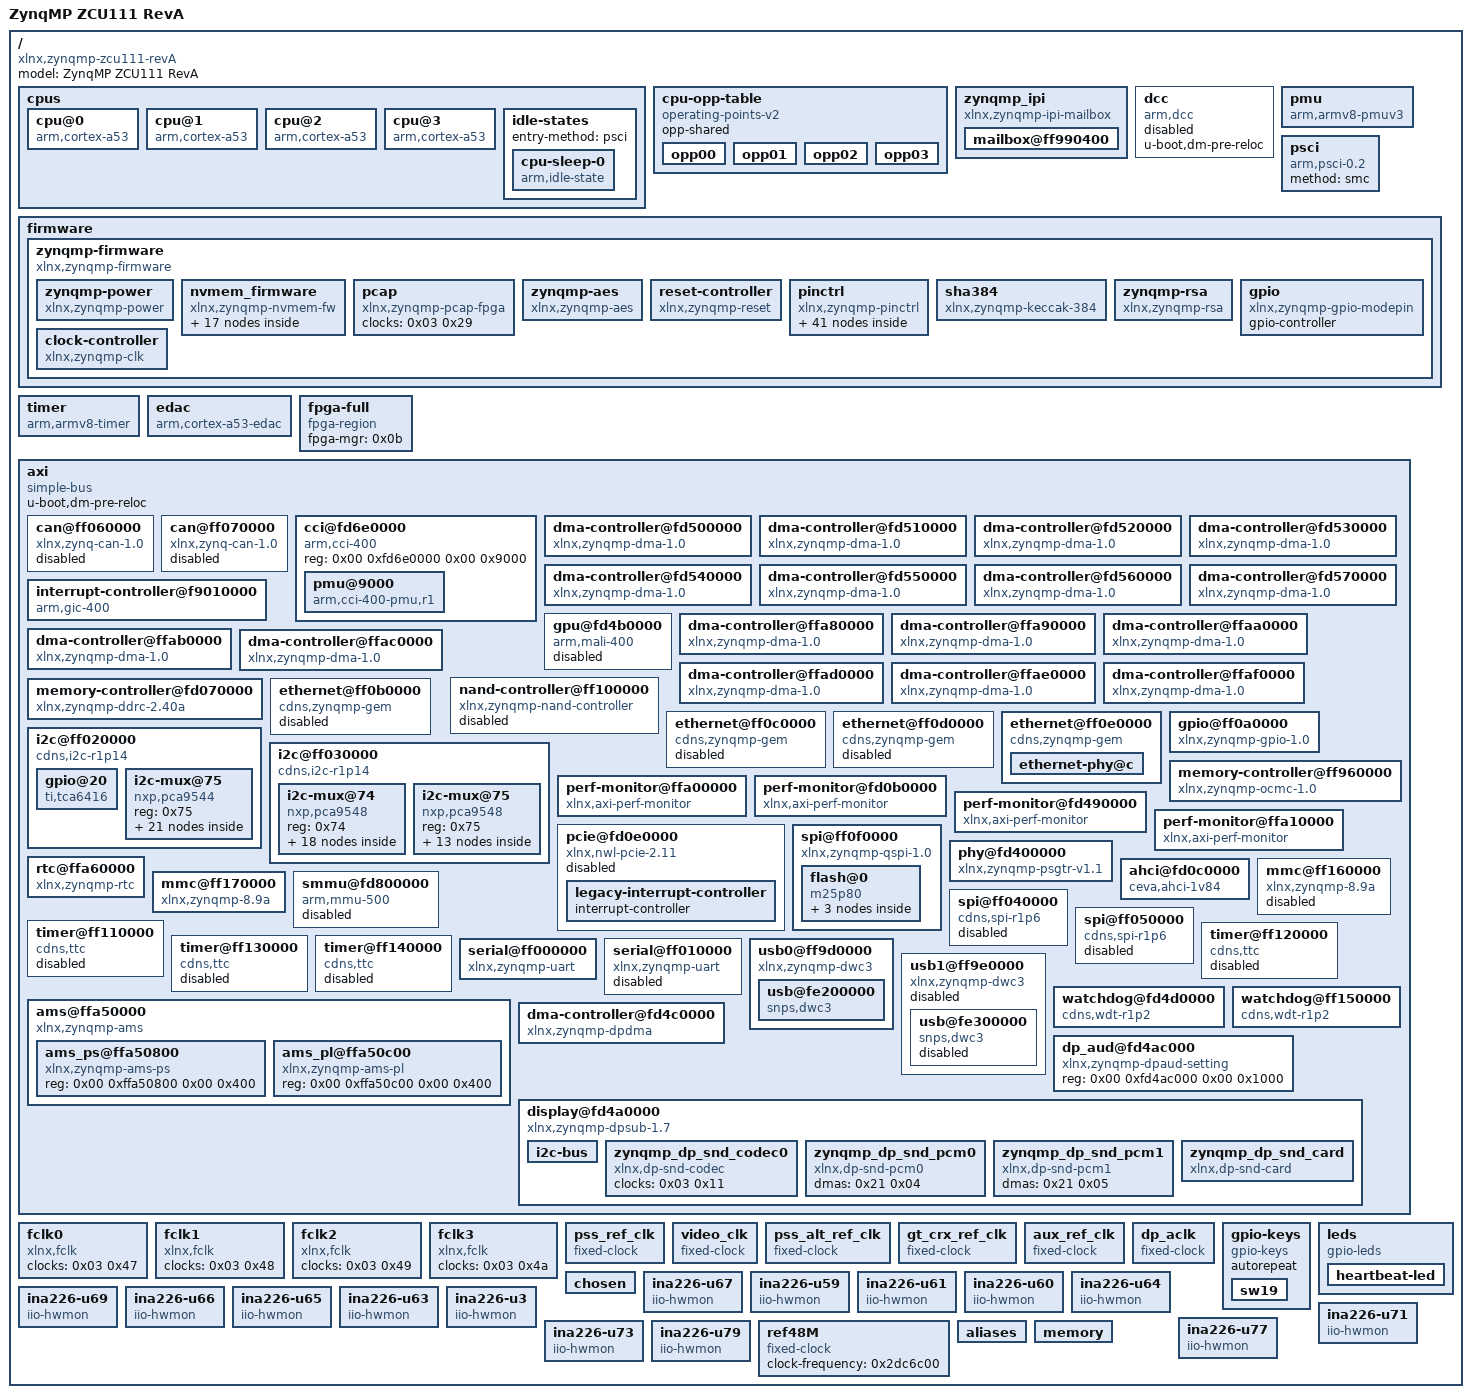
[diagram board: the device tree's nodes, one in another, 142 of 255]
/dts-v1/;

/ {
	compatible = "xlnx,zynqmp-zcu111-revA\0xlnx,zynqmp-zcu111\0xlnx,zynqmp";
	#address-cells = <0x02>;
	#size-cells = <0x02>;
	model = "ZynqMP ZCU111 RevA";

	cpus {
		#address-cells = <0x01>;
		#size-cells = <0x00>;

		cpu@0 {
			compatible = "arm,cortex-a53";
			device_type = "cpu";
			enable-method = "psci";
			operating-points-v2 = <0x01>;
			reg = <0x00>;
			cpu-idle-states = <0x02>;
			clocks = <0x03 0x0a>;
			phandle = <0x34>;
		};

		cpu@1 {
			compatible = "arm,cortex-a53";
			device_type = "cpu";
			enable-method = "psci";
			reg = <0x01>;
			operating-points-v2 = <0x01>;
			cpu-idle-states = <0x02>;
			phandle = <0x35>;
		};

		cpu@2 {
			compatible = "arm,cortex-a53";
			device_type = "cpu";
			enable-method = "psci";
			reg = <0x02>;
			operating-points-v2 = <0x01>;
			cpu-idle-states = <0x02>;
			phandle = <0x36>;
		};

		cpu@3 {
			compatible = "arm,cortex-a53";
			device_type = "cpu";
			enable-method = "psci";
			reg = <0x03>;
			operating-points-v2 = <0x01>;
			cpu-idle-states = <0x02>;
			phandle = <0x37>;
		};

		idle-states {
			entry-method = "psci";

			cpu-sleep-0 {
				compatible = "arm,idle-state";
				arm,psci-suspend-param = <0x40000000>;
				local-timer-stop;
				entry-latency-us = <0x12c>;
				exit-latency-us = <0x258>;
				min-residency-us = <0x2710>;
				phandle = <0x02>;
			};
		};
	};

	cpu-opp-table {
		compatible = "operating-points-v2";
		opp-shared;
		phandle = <0x01>;

		opp00 {
			opp-hz = <0x00 0x47868bf4>;
			opp-microvolt = <0xf4240>;
			clock-latency-ns = <0x7a120>;
		};

		opp01 {
			opp-hz = <0x00 0x23c345fa>;
			opp-microvolt = <0xf4240>;
			clock-latency-ns = <0x7a120>;
		};

		opp02 {
			opp-hz = <0x00 0x17d783fc>;
			opp-microvolt = <0xf4240>;
			clock-latency-ns = <0x7a120>;
		};

		opp03 {
			opp-hz = <0x00 0x11e1a2fd>;
			opp-microvolt = <0xf4240>;
			clock-latency-ns = <0x7a120>;
		};
	};

	zynqmp_ipi {
		u-boot,dm-pre-reloc;
		compatible = "xlnx,zynqmp-ipi-mailbox";
		interrupt-parent = <0x04>;
		interrupts = <0x00 0x23 0x04>;
		xlnx,ipi-id = <0x00>;
		#address-cells = <0x02>;
		#size-cells = <0x02>;
		ranges;
		phandle = <0x38>;

		mailbox@ff990400 {
			u-boot,dm-pre-reloc;
			reg = <0x00 0xff9905c0 0x00 0x20 0x00 0xff9905e0 0x00 0x20 0x00 0xff990e80 0x00 0x20 0x00 0xff990ea0 0x00 0x20>;
			reg-names = "local_request_region\0local_response_region\0remote_request_region\0remote_response_region";
			#mbox-cells = <0x01>;
			xlnx,ipi-id = <0x04>;
			phandle = <0x05>;
		};
	};

	dcc {
		compatible = "arm,dcc";
		status = "disabled";
		u-boot,dm-pre-reloc;
		phandle = <0x39>;
	};

	pmu {
		compatible = "arm,armv8-pmuv3";
		interrupt-parent = <0x04>;
		interrupts = <0x00 0x8f 0x04 0x00 0x90 0x04 0x00 0x91 0x04 0x00 0x92 0x04>;
	};

	psci {
		compatible = "arm,psci-0.2";
		method = "smc";
	};

	firmware {

		zynqmp-firmware {
			compatible = "xlnx,zynqmp-firmware";
			u-boot,dm-pre-reloc;
			method = "smc";
			#power-domain-cells = <0x01>;
			phandle = <0x0c>;

			zynqmp-power {
				u-boot,dm-pre-reloc;
				compatible = "xlnx,zynqmp-power";
				interrupt-parent = <0x04>;
				interrupts = <0x00 0x23 0x04>;
				mboxes = <0x05 0x00 0x05 0x01>;
				mbox-names = "tx\0rx";
				phandle = <0x3a>;
			};

			nvmem_firmware {
				compatible = "xlnx,zynqmp-nvmem-fw";
				#address-cells = <0x01>;
				#size-cells = <0x01>;

				soc_revision@0 {
					reg = <0x00 0x04>;
					phandle = <0x3b>;
				};

				efuse_dna@c {
					reg = <0x0c 0x0c>;
					phandle = <0x3c>;
				};

				efuse_usr0@20 {
					reg = <0x20 0x04>;
					phandle = <0x3d>;
				};

				efuse_usr1@24 {
					reg = <0x24 0x04>;
					phandle = <0x3e>;
				};

				efuse_usr2@28 {
					reg = <0x28 0x04>;
					phandle = <0x3f>;
				};

				efuse_usr3@2c {
					reg = <0x2c 0x04>;
					phandle = <0x40>;
				};

				efuse_usr4@30 {
					reg = <0x30 0x04>;
					phandle = <0x41>;
				};

				efuse_usr5@34 {
					reg = <0x34 0x04>;
					phandle = <0x42>;
				};

				efuse_usr6@38 {
					reg = <0x38 0x04>;
					phandle = <0x43>;
				};

				efuse_usr7@3c {
					reg = <0x3c 0x04>;
					phandle = <0x44>;
				};

				efuse_miscusr@40 {
					reg = <0x40 0x04>;
					phandle = <0x45>;
				};

				efuse_chash@50 {
					reg = <0x50 0x04>;
					phandle = <0x46>;
				};

				efuse_pufmisc@54 {
					reg = <0x54 0x04>;
					phandle = <0x47>;
				};

				efuse_sec@58 {
					reg = <0x58 0x04>;
					phandle = <0x48>;
				};

				efuse_spkid@5c {
					reg = <0x5c 0x04>;
					phandle = <0x49>;
				};

				efuse_ppk0hash@a0 {
					reg = <0xa0 0x30>;
					phandle = <0x4a>;
				};

				efuse_ppk1hash@d0 {
					reg = <0xd0 0x30>;
					phandle = <0x4b>;
				};
			};

			pcap {
				compatible = "xlnx,zynqmp-pcap-fpga";
				clock-names = "ref_clk";
				clocks = <0x03 0x29>;
				phandle = <0x0b>;
			};

			zynqmp-aes {
				compatible = "xlnx,zynqmp-aes";
				phandle = <0x4c>;
			};

			reset-controller {
				compatible = "xlnx,zynqmp-reset";
				#reset-cells = <0x01>;
				phandle = <0x0e>;
			};

			pinctrl {
				compatible = "xlnx,zynqmp-pinctrl";
				status = "okay";
				phandle = <0x4d>;

				i2c0-default {
					phandle = <0x12>;

					mux {
						groups = "i2c0_3_grp";
						function = "i2c0";
					};

					conf {
						groups = "i2c0_3_grp";
						bias-pull-up;
						slew-rate = <0x01>;
						power-source = <0x01>;
					};
				};

				i2c0-gpio {
					phandle = <0x13>;

					mux {
						groups = "gpio0_14_grp\0gpio0_15_grp";
						function = "gpio0";
					};

					conf {
						groups = "gpio0_14_grp\0gpio0_15_grp";
						slew-rate = <0x01>;
						power-source = <0x01>;
					};
				};

				i2c1-default {
					phandle = <0x15>;

					mux {
						groups = "i2c1_4_grp";
						function = "i2c1";
					};

					conf {
						groups = "i2c1_4_grp";
						bias-pull-up;
						slew-rate = <0x01>;
						power-source = <0x01>;
					};
				};

				i2c1-gpio {
					phandle = <0x16>;

					mux {
						groups = "gpio0_16_grp\0gpio0_17_grp";
						function = "gpio0";
					};

					conf {
						groups = "gpio0_16_grp\0gpio0_17_grp";
						slew-rate = <0x01>;
						power-source = <0x01>;
					};
				};

				uart0-default {
					phandle = <0x1d>;

					mux {
						groups = "uart0_4_grp";
						function = "uart0";
					};

					conf {
						groups = "uart0_4_grp";
						slew-rate = <0x01>;
						power-source = <0x01>;
					};

					conf-rx {
						pins = "MIO18";
						bias-high-impedance;
					};

					conf-tx {
						pins = "MIO19";
						bias-disable;
					};
				};

				usb0-default {
					phandle = <0x1f>;

					mux {
						groups = "usb0_0_grp";
						function = "usb0";
					};

					conf {
						groups = "usb0_0_grp";
						slew-rate = <0x01>;
						power-source = <0x01>;
					};

					conf-rx {
						pins = "MIO52\0MIO53\0MIO55";
						bias-high-impedance;
					};

					conf-tx {
						pins = "MIO54\0MIO56\0MIO57\0MIO58\0MIO59\0MIO60\0MIO61\0MIO62\0MIO63";
						bias-disable;
					};
				};

				gem3-default {
					phandle = <0x10>;

					mux {
						function = "ethernet3";
						groups = "ethernet3_0_grp";
					};

					conf {
						groups = "ethernet3_0_grp";
						slew-rate = <0x01>;
						power-source = <0x01>;
					};

					conf-rx {
						pins = "MIO70\0MIO71\0MIO72\0MIO73\0MIO74\0MIO75";
						bias-high-impedance;
						low-power-disable;
					};

					conf-tx {
						pins = "MIO64\0MIO65\0MIO66\0MIO67\0MIO68\0MIO69";
						bias-disable;
						low-power-enable;
					};

					mux-mdio {
						function = "mdio3";
						groups = "mdio3_0_grp";
					};

					conf-mdio {
						groups = "mdio3_0_grp";
						slew-rate = <0x01>;
						power-source = <0x01>;
						bias-disable;
					};
				};

				sdhci1-default {
					phandle = <0x1c>;

					mux {
						groups = "sdio1_0_grp";
						function = "sdio1";
					};

					conf {
						groups = "sdio1_0_grp";
						slew-rate = <0x01>;
						power-source = <0x01>;
						bias-disable;
					};

					mux-cd {
						groups = "sdio1_cd_0_grp";
						function = "sdio1_cd";
					};

					conf-cd {
						groups = "sdio1_cd_0_grp";
						bias-high-impedance;
						bias-pull-up;
						slew-rate = <0x01>;
						power-source = <0x01>;
					};
				};

				gpio-default {
					phandle = <0x11>;

					mux {
						function = "gpio0";
						groups = "gpio0_22_grp\0gpio0_23_grp";
					};

					conf {
						groups = "gpio0_22_grp\0gpio0_23_grp";
						slew-rate = <0x01>;
						power-source = <0x01>;
					};

					mux-msp {
						function = "gpio0";
						groups = "gpio0_13_grp\0gpio0_38_grp";
					};

					conf-msp {
						groups = "gpio0_13_grp\0gpio0_38_grp";
						slew-rate = <0x01>;
						power-source = <0x01>;
					};

					conf-pull-up {
						pins = "MIO22";
						bias-pull-up;
					};

					conf-pull-none {
						pins = "MIO13\0MIO23\0MIO38";
						bias-disable;
					};
				};
			};

			sha384 {
				compatible = "xlnx,zynqmp-keccak-384";
				phandle = <0x4e>;
			};

			zynqmp-rsa {
				compatible = "xlnx,zynqmp-rsa";
				phandle = <0x4f>;
			};

			gpio {
				compatible = "xlnx,zynqmp-gpio-modepin";
				gpio-controller;
				#gpio-cells = <0x02>;
				phandle = <0x1e>;
			};

			clock-controller {
				u-boot,dm-pre-reloc;
				#clock-cells = <0x01>;
				compatible = "xlnx,zynqmp-clk";
				clocks = <0x06 0x07 0x08 0x09 0x0a>;
				clock-names = "pss_ref_clk\0video_clk\0pss_alt_ref_clk\0aux_ref_clk\0gt_crx_ref_clk";
				phandle = <0x03>;
			};
		};
	};

	timer {
		compatible = "arm,armv8-timer";
		interrupt-parent = <0x04>;
		interrupts = <0x01 0x0d 0xf08 0x01 0x0e 0xf08 0x01 0x0b 0xf08 0x01 0x0a 0xf08>;
	};

	edac {
		compatible = "arm,cortex-a53-edac";
	};

	fpga-full {
		compatible = "fpga-region";
		fpga-mgr = <0x0b>;
		#address-cells = <0x02>;
		#size-cells = <0x02>;
		ranges;
		phandle = <0x50>;
	};

	axi {
		compatible = "simple-bus";
		u-boot,dm-pre-reloc;
		#address-cells = <0x02>;
		#size-cells = <0x02>;
		ranges;
		phandle = <0x51>;

		can@ff060000 {
			compatible = "xlnx,zynq-can-1.0";
			status = "disabled";
			clock-names = "can_clk\0pclk";
			reg = <0x00 0xff060000 0x00 0x1000>;
			interrupts = <0x00 0x17 0x04>;
			interrupt-parent = <0x04>;
			tx-fifo-depth = <0x40>;
			rx-fifo-depth = <0x40>;
			power-domains = <0x0c 0x2f>;
			clocks = <0x03 0x3f 0x03 0x1f>;
			phandle = <0x52>;
		};

		can@ff070000 {
			compatible = "xlnx,zynq-can-1.0";
			status = "disabled";
			clock-names = "can_clk\0pclk";
			reg = <0x00 0xff070000 0x00 0x1000>;
			interrupts = <0x00 0x18 0x04>;
			interrupt-parent = <0x04>;
			tx-fifo-depth = <0x40>;
			rx-fifo-depth = <0x40>;
			power-domains = <0x0c 0x30>;
			clocks = <0x03 0x40 0x03 0x1f>;
			phandle = <0x53>;
		};

		cci@fd6e0000 {
			compatible = "arm,cci-400";
			status = "okay";
			reg = <0x00 0xfd6e0000 0x00 0x9000>;
			ranges = <0x00 0x00 0xfd6e0000 0x10000>;
			#address-cells = <0x01>;
			#size-cells = <0x01>;
			phandle = <0x54>;

			pmu@9000 {
				compatible = "arm,cci-400-pmu,r1";
				reg = <0x9000 0x5000>;
				interrupt-parent = <0x04>;
				interrupts = <0x00 0x7b 0x04 0x00 0x7b 0x04 0x00 0x7b 0x04 0x00 0x7b 0x04 0x00 0x7b 0x04>;
			};
		};

		dma-controller@fd500000 {
			status = "okay";
			compatible = "xlnx,zynqmp-dma-1.0";
			reg = <0x00 0xfd500000 0x00 0x1000>;
			interrupt-parent = <0x04>;
			interrupts = <0x00 0x7c 0x04>;
			clock-names = "clk_main\0clk_apb";
			xlnx,bus-width = <0x80>;
			#stream-id-cells = <0x01>;
			iommus = <0x0d 0x14e8>;
			power-domains = <0x0c 0x2a>;
			#dma-cells = <0x01>;
			clocks = <0x03 0x13 0x03 0x1f>;
			phandle = <0x55>;
		};

		dma-controller@fd510000 {
			status = "okay";
			compatible = "xlnx,zynqmp-dma-1.0";
			reg = <0x00 0xfd510000 0x00 0x1000>;
			interrupt-parent = <0x04>;
			interrupts = <0x00 0x7d 0x04>;
			clock-names = "clk_main\0clk_apb";
			xlnx,bus-width = <0x80>;
			#stream-id-cells = <0x01>;
			iommus = <0x0d 0x14e9>;
			power-domains = <0x0c 0x2a>;
			#dma-cells = <0x01>;
			clocks = <0x03 0x13 0x03 0x1f>;
			phandle = <0x56>;
		};

		dma-controller@fd520000 {
			status = "okay";
			compatible = "xlnx,zynqmp-dma-1.0";
			reg = <0x00 0xfd520000 0x00 0x1000>;
			interrupt-parent = <0x04>;
			interrupts = <0x00 0x7e 0x04>;
			clock-names = "clk_main\0clk_apb";
			xlnx,bus-width = <0x80>;
			#stream-id-cells = <0x01>;
			iommus = <0x0d 0x14ea>;
			power-domains = <0x0c 0x2a>;
			#dma-cells = <0x01>;
			clocks = <0x03 0x13 0x03 0x1f>;
			phandle = <0x57>;
		};

		dma-controller@fd530000 {
			status = "okay";
			compatible = "xlnx,zynqmp-dma-1.0";
			reg = <0x00 0xfd530000 0x00 0x1000>;
			interrupt-parent = <0x04>;
			interrupts = <0x00 0x7f 0x04>;
			clock-names = "clk_main\0clk_apb";
			xlnx,bus-width = <0x80>;
			#stream-id-cells = <0x01>;
			iommus = <0x0d 0x14eb>;
			power-domains = <0x0c 0x2a>;
			#dma-cells = <0x01>;
			clocks = <0x03 0x13 0x03 0x1f>;
			phandle = <0x58>;
		};

		dma-controller@fd540000 {
			status = "okay";
			compatible = "xlnx,zynqmp-dma-1.0";
			reg = <0x00 0xfd540000 0x00 0x1000>;
			interrupt-parent = <0x04>;
			interrupts = <0x00 0x80 0x04>;
			clock-names = "clk_main\0clk_apb";
			xlnx,bus-width = <0x80>;
			#stream-id-cells = <0x01>;
			iommus = <0x0d 0x14ec>;
			power-domains = <0x0c 0x2a>;
			#dma-cells = <0x01>;
			clocks = <0x03 0x13 0x03 0x1f>;
			phandle = <0x59>;
		};

		dma-controller@fd550000 {
			status = "okay";
			compatible = "xlnx,zynqmp-dma-1.0";
			reg = <0x00 0xfd550000 0x00 0x1000>;
			interrupt-parent = <0x04>;
			interrupts = <0x00 0x81 0x04>;
			clock-names = "clk_main\0clk_apb";
			xlnx,bus-width = <0x80>;
			#stream-id-cells = <0x01>;
			iommus = <0x0d 0x14ed>;
			power-domains = <0x0c 0x2a>;
			#dma-cells = <0x01>;
			clocks = <0x03 0x13 0x03 0x1f>;
			phandle = <0x5a>;
		};

		dma-controller@fd560000 {
			status = "okay";
			compatible = "xlnx,zynqmp-dma-1.0";
			reg = <0x00 0xfd560000 0x00 0x1000>;
			interrupt-parent = <0x04>;
			interrupts = <0x00 0x82 0x04>;
			clock-names = "clk_main\0clk_apb";
			xlnx,bus-width = <0x80>;
			#stream-id-cells = <0x01>;
			iommus = <0x0d 0x14ee>;
			power-domains = <0x0c 0x2a>;
			#dma-cells = <0x01>;
			clocks = <0x03 0x13 0x03 0x1f>;
			phandle = <0x5b>;
		};

		dma-controller@fd570000 {
			status = "okay";
			compatible = "xlnx,zynqmp-dma-1.0";
			reg = <0x00 0xfd570000 0x00 0x1000>;
			interrupt-parent = <0x04>;
			interrupts = <0x00 0x83 0x04>;
			clock-names = "clk_main\0clk_apb";
			xlnx,bus-width = <0x80>;
			#stream-id-cells = <0x01>;
			iommus = <0x0d 0x14ef>;
			power-domains = <0x0c 0x2a>;
			#dma-cells = <0x01>;
			clocks = <0x03 0x13 0x03 0x1f>;
			phandle = <0x5c>;
		};

		interrupt-controller@f9010000 {
			compatible = "arm,gic-400";
			#interrupt-cells = <0x03>;
			reg = <0x00 0xf9010000 0x00 0x10000 0x00 0xf9020000 0x00 0x20000 0x00 0xf9040000 0x00 0x20000 0x00 0xf9060000 0x00 0x20000>;
			interrupt-controller;
			interrupt-parent = <0x04>;
			interrupts = <0x01 0x09 0xf04>;
			num_cpus = <0x02>;
			num_interrupts = <0x60>;
			phandle = <0x04>;
		};

		gpu@fd4b0000 {
			status = "disabled";
			compatible = "arm,mali-400\0arm,mali-utgard";
			reg = <0x00 0xfd4b0000 0x00 0x10000>;
			interrupt-parent = <0x04>;
			interrupts = <0x00 0x84 0x04 0x00 0x84 0x04 0x00 0x84 0x04 0x00 0x84 0x04 0x00 0x84 0x04 0x00 0x84 0x04>;
			interrupt-names = "IRQGP\0IRQGPMMU\0IRQPP0\0IRQPPMMU0\0IRQPP1\0IRQPPMMU1";
			clock-names = "gpu\0gpu_pp0\0gpu_pp1";
			power-domains = <0x0c 0x3a>;
			clocks = <0x03 0x18 0x03 0x19 0x03 0x1a>;
			phandle = <0x5d>;
		};

		dma-controller@ffa80000 {
			status = "okay";
			compatible = "xlnx,zynqmp-dma-1.0";
			reg = <0x00 0xffa80000 0x00 0x1000>;
			interrupt-parent = <0x04>;
			interrupts = <0x00 0x4d 0x04>;
			clock-names = "clk_main\0clk_apb";
			xlnx,bus-width = <0x40>;
			#stream-id-cells = <0x01>;
			power-domains = <0x0c 0x2b>;
			#dma-cells = <0x01>;
			clocks = <0x03 0x44 0x03 0x1f>;
			phandle = <0x5e>;
		};

		dma-controller@ffa90000 {
			status = "okay";
			compatible = "xlnx,zynqmp-dma-1.0";
			reg = <0x00 0xffa90000 0x00 0x1000>;
			interrupt-parent = <0x04>;
			interrupts = <0x00 0x4e 0x04>;
			clock-names = "clk_main\0clk_apb";
			xlnx,bus-width = <0x40>;
			#stream-id-cells = <0x01>;
			power-domains = <0x0c 0x2b>;
			#dma-cells = <0x01>;
			clocks = <0x03 0x44 0x03 0x1f>;
			phandle = <0x5f>;
		};

		dma-controller@ffaa0000 {
			status = "okay";
			compatible = "xlnx,zynqmp-dma-1.0";
			reg = <0x00 0xffaa0000 0x00 0x1000>;
			interrupt-parent = <0x04>;
			interrupts = <0x00 0x4f 0x04>;
			clock-names = "clk_main\0clk_apb";
			xlnx,bus-width = <0x40>;
			#stream-id-cells = <0x01>;
			power-domains = <0x0c 0x2b>;
			#dma-cells = <0x01>;
			clocks = <0x03 0x44 0x03 0x1f>;
			phandle = <0x60>;
		};

		dma-controller@ffab0000 {
			status = "okay";
			compatible = "xlnx,zynqmp-dma-1.0";
			reg = <0x00 0xffab0000 0x00 0x1000>;
			interrupt-parent = <0x04>;
			interrupts = <0x00 0x50 0x04>;
			clock-names = "clk_main\0clk_apb";
			xlnx,bus-width = <0x40>;
			#stream-id-cells = <0x01>;
			power-domains = <0x0c 0x2b>;
			#dma-cells = <0x01>;
			clocks = <0x03 0x44 0x03 0x1f>;
			phandle = <0x61>;
		};

		dma-controller@ffac0000 {
			status = "okay";
			compatible = "xlnx,zynqmp-dma-1.0";
			reg = <0x00 0xffac0000 0x00 0x1000>;
			interrupt-parent = <0x04>;
			interrupts = <0x00 0x51 0x04>;
			clock-names = "clk_main\0clk_apb";
			xlnx,bus-width = <0x40>;
			#stream-id-cells = <0x01>;
			power-domains = <0x0c 0x2b>;
			#dma-cells = <0x01>;
			clocks = <0x03 0x44 0x03 0x1f>;
			phandle = <0x62>;
		};

		dma-controller@ffad0000 {
			status = "okay";
			compatible = "xlnx,zynqmp-dma-1.0";
			reg = <0x00 0xffad0000 0x00 0x1000>;
			interrupt-parent = <0x04>;
			interrupts = <0x00 0x52 0x04>;
			clock-names = "clk_main\0clk_apb";
			xlnx,bus-width = <0x40>;
			#stream-id-cells = <0x01>;
			power-domains = <0x0c 0x2b>;
			#dma-cells = <0x01>;
			clocks = <0x03 0x44 0x03 0x1f>;
			phandle = <0x63>;
		};

		dma-controller@ffae0000 {
			status = "okay";
			compatible = "xlnx,zynqmp-dma-1.0";
			reg = <0x00 0xffae0000 0x00 0x1000>;
			interrupt-parent = <0x04>;
			interrupts = <0x00 0x53 0x04>;
			clock-names = "clk_main\0clk_apb";
			xlnx,bus-width = <0x40>;
			#stream-id-cells = <0x01>;
			power-domains = <0x0c 0x2b>;
			#dma-cells = <0x01>;
			clocks = <0x03 0x44 0x03 0x1f>;
			phandle = <0x64>;
		};

		dma-controller@ffaf0000 {
			status = "okay";
			compatible = "xlnx,zynqmp-dma-1.0";
			reg = <0x00 0xffaf0000 0x00 0x1000>;
			interrupt-parent = <0x04>;
			interrupts = <0x00 0x54 0x04>;
			clock-names = "clk_main\0clk_apb";
			xlnx,bus-width = <0x40>;
			#stream-id-cells = <0x01>;
			power-domains = <0x0c 0x2b>;
			#dma-cells = <0x01>;
			clocks = <0x03 0x44 0x03 0x1f>;
			phandle = <0x65>;
		};

		memory-controller@fd070000 {
			compatible = "xlnx,zynqmp-ddrc-2.40a";
			reg = <0x00 0xfd070000 0x00 0x30000>;
			interrupt-parent = <0x04>;
			interrupts = <0x00 0x70 0x04>;
			phandle = <0x66>;
		};

		nand-controller@ff100000 {
			compatible = "xlnx,zynqmp-nand-controller\0arasan,nfc-v3p10";
			status = "disabled";
			reg = <0x00 0xff100000 0x00 0x1000>;
			clock-names = "controller\0bus";
			interrupt-parent = <0x04>;
			interrupts = <0x00 0x0e 0x04>;
			#address-cells = <0x01>;
			#size-cells = <0x00>;
			#stream-id-cells = <0x01>;
			iommus = <0x0d 0x872>;
			power-domains = <0x0c 0x2c>;
			clocks = <0x03 0x3c 0x03 0x1f>;
			phandle = <0x67>;
		};

		ethernet@ff0b0000 {
			compatible = "cdns,zynqmp-gem\0cdns,gem";
			status = "disabled";
			interrupt-parent = <0x04>;
			interrupts = <0x00 0x39 0x04 0x00 0x39 0x04>;
			reg = <0x00 0xff0b0000 0x00 0x1000>;
			clock-names = "pclk\0hclk\0tx_clk\0rx_clk\0tsu_clk";
			#address-cells = <0x01>;
			#size-cells = <0x00>;
			#stream-id-cells = <0x01>;
			iommus = <0x0d 0x874>;
			power-domains = <0x0c 0x1d>;
			resets = <0x0e 0x1d>;
			clocks = <0x03 0x1f 0x03 0x68 0x03 0x2d 0x03 0x31 0x03 0x2c>;
			phandle = <0x68>;
		};

		ethernet@ff0c0000 {
			compatible = "cdns,zynqmp-gem\0cdns,gem";
			status = "disabled";
			interrupt-parent = <0x04>;
			interrupts = <0x00 0x3b 0x04 0x00 0x3b 0x04>;
			reg = <0x00 0xff0c0000 0x00 0x1000>;
			clock-names = "pclk\0hclk\0tx_clk\0rx_clk\0tsu_clk";
			#address-cells = <0x01>;
			#size-cells = <0x00>;
			#stream-id-cells = <0x01>;
			iommus = <0x0d 0x875>;
			power-domains = <0x0c 0x1e>;
			resets = <0x0e 0x1e>;
			clocks = <0x03 0x1f 0x03 0x69 0x03 0x2e 0x03 0x32 0x03 0x2c>;
			phandle = <0x69>;
		};

		ethernet@ff0d0000 {
			compatible = "cdns,zynqmp-gem\0cdns,gem";
			status = "disabled";
			interrupt-parent = <0x04>;
			interrupts = <0x00 0x3d 0x04 0x00 0x3d 0x04>;
			reg = <0x00 0xff0d0000 0x00 0x1000>;
			clock-names = "pclk\0hclk\0tx_clk\0rx_clk\0tsu_clk";
			#address-cells = <0x01>;
			#size-cells = <0x00>;
			#stream-id-cells = <0x01>;
			iommus = <0x0d 0x876>;
			power-domains = <0x0c 0x1f>;
			resets = <0x0e 0x1f>;
			clocks = <0x03 0x1f 0x03 0x6a 0x03 0x2f 0x03 0x33 0x03 0x2c>;
			phandle = <0x6a>;
		};

		ethernet@ff0e0000 {
			compatible = "cdns,zynqmp-gem\0cdns,gem";
			status = "okay";
			interrupt-parent = <0x04>;
			interrupts = <0x00 0x3f 0x04 0x00 0x3f 0x04>;
			reg = <0x00 0xff0e0000 0x00 0x1000>;
			clock-names = "pclk\0hclk\0tx_clk\0rx_clk\0tsu_clk";
			#address-cells = <0x01>;
			#size-cells = <0x00>;
			#stream-id-cells = <0x01>;
			iommus = <0x0d 0x877>;
			power-domains = <0x0c 0x20>;
			resets = <0x0e 0x20>;
			clocks = <0x03 0x1f 0x03 0x6b 0x03 0x30 0x03 0x34 0x03 0x2c>;
			phy-handle = <0x0f>;
			pinctrl-names = "default";
			pinctrl-0 = <0x10>;
			phy-mode = "rgmii-id";
			xlnx,ptp-enet-clock = <0x00>;
			local-mac-address = [ff ff ff ff ff ff];
			phandle = <0x6b>;

			ethernet-phy@c {
				reg = <0x0c>;
				ti,rx-internal-delay = <0x08>;
				ti,tx-internal-delay = <0x0a>;
				ti,fifo-depth = <0x01>;
				ti,dp83867-rxctrl-strap-quirk;
				phandle = <0x0f>;
			};
		};

		gpio@ff0a0000 {
			compatible = "xlnx,zynqmp-gpio-1.0";
			status = "okay";
			#gpio-cells = <0x02>;
			gpio-controller;
			interrupt-parent = <0x04>;
			interrupts = <0x00 0x10 0x04>;
			interrupt-controller;
			#interrupt-cells = <0x02>;
			reg = <0x00 0xff0a0000 0x00 0x1000>;
			power-domains = <0x0c 0x2e>;
			clocks = <0x03 0x1f>;
			pinctrl-names = "default";
			pinctrl-0 = <0x11>;
			emio-gpio-width = <0x20>;
			gpio-mask-high = <0x00>;
			gpio-mask-low = <0x5600>;
			phandle = <0x14>;
		};

		i2c@ff020000 {
			compatible = "cdns,i2c-r1p14";
			status = "okay";
			interrupt-parent = <0x04>;
			interrupts = <0x00 0x11 0x04>;
			reg = <0x00 0xff020000 0x00 0x1000>;
			#address-cells = <0x01>;
			#size-cells = <0x00>;
			power-domains = <0x0c 0x25>;
			clocks = <0x03 0x3d>;
			pinctrl-names = "default\0gpio";
			pinctrl-0 = <0x12>;
			pinctrl-1 = <0x13>;
			scl-gpios = <0x14 0x0e 0x00>;
			sda-gpios = <0x14 0x0f 0x00>;
			clock-frequency = <0x61a80>;
			phandle = <0x6c>;

			gpio@20 {
				compatible = "ti,tca6416";
				reg = <0x20>;
				gpio-controller;
				#gpio-cells = <0x02>;
				phandle = <0x6d>;
			};

			i2c-mux@75 {
				compatible = "nxp,pca9544";
				#address-cells = <0x01>;
				#size-cells = <0x00>;
				reg = <0x75>;

				i2c@0 {
					#address-cells = <0x01>;
					#size-cells = <0x00>;
					reg = <0x00>;

					ina226@40 {
						compatible = "ti,ina226";
						#io-channel-cells = <0x01>;
						label = "ina226-u67";
						reg = <0x40>;
						shunt-resistor = <0x7d0>;
						phandle = <0x26>;
					};

					ina226@41 {
						compatible = "ti,ina226";
						#io-channel-cells = <0x01>;
						label = "ina226-u59";
						reg = <0x41>;
						shunt-resistor = <0x1388>;
						phandle = <0x27>;
					};

					ina226@42 {
						compatible = "ti,ina226";
						#io-channel-cells = <0x01>;
						label = "ina226-u61";
						reg = <0x42>;
						shunt-resistor = <0x1388>;
						phandle = <0x28>;
					};

					ina226@43 {
						compatible = "ti,ina226";
						#io-channel-cells = <0x01>;
						label = "ina226-u60";
						reg = <0x43>;
						shunt-resistor = <0x1388>;
						phandle = <0x29>;
					};

					ina226@45 {
						compatible = "ti,ina226";
						#io-channel-cells = <0x01>;
						label = "ina226-u64";
						reg = <0x45>;
						shunt-resistor = <0x1388>;
						phandle = <0x2a>;
					};

					ina226@46 {
						compatible = "ti,ina226";
						#io-channel-cells = <0x01>;
						label = "ina226-u69";
						reg = <0x46>;
						shunt-resistor = <0x7d0>;
						phandle = <0x2b>;
					};

					ina226@47 {
						compatible = "ti,ina226";
						#io-channel-cells = <0x01>;
						label = "ina226-u66";
						reg = <0x47>;
						shunt-resistor = <0x1388>;
						phandle = <0x2c>;
					};

					ina226@48 {
						compatible = "ti,ina226";
						#io-channel-cells = <0x01>;
						label = "ina226-u65";
						reg = <0x48>;
						shunt-resistor = <0x1388>;
						phandle = <0x2d>;
					};

					ina226@49 {
						compatible = "ti,ina226";
						#io-channel-cells = <0x01>;
						label = "ina226-u63";
						reg = <0x49>;
						shunt-resistor = <0x1388>;
						phandle = <0x2e>;
					};

					ina226@4a {
						compatible = "ti,ina226";
						#io-channel-cells = <0x01>;
						label = "ina226-u3";
						reg = <0x4a>;
						shunt-resistor = <0x1388>;
						phandle = <0x2f>;
					};

					ina226@4b {
						compatible = "ti,ina226";
						#io-channel-cells = <0x01>;
						label = "ina226-u71";
						reg = <0x4b>;
						shunt-resistor = <0x1388>;
						phandle = <0x30>;
					};

					ina226@4c {
						compatible = "ti,ina226";
						#io-channel-cells = <0x01>;
						label = "ina226-u77";
						reg = <0x4c>;
						shunt-resistor = <0x1388>;
						phandle = <0x31>;
					};

					ina226@4d {
						compatible = "ti,ina226";
						#io-channel-cells = <0x01>;
						label = "ina226-u73";
						reg = <0x4d>;
						shunt-resistor = <0x1388>;
						phandle = <0x32>;
					};

					ina226@4e {
						compatible = "ti,ina226";
						#io-channel-cells = <0x01>;
						label = "ina226-u79";
						reg = <0x4e>;
						shunt-resistor = <0x1388>;
						phandle = <0x33>;
					};
				};

				i2c@1 {
					#address-cells = <0x01>;
					#size-cells = <0x00>;
					reg = <0x01>;
				};

				i2c@2 {
					#address-cells = <0x01>;
					#size-cells = <0x00>;
					reg = <0x02>;

					irps5401@43 {
						compatible = "infineon,irps5401";
						reg = <0x43>;
						phandle = <0x6e>;
					};

					irps5401@44 {
						compatible = "infineon,irps5401";
						reg = <0x44>;
						phandle = <0x6f>;
					};

					irps5401@45 {
						compatible = "infineon,irps5401";
						reg = <0x45>;
						phandle = <0x70>;
					};
				};

				i2c@3 {
					#address-cells = <0x01>;
					#size-cells = <0x00>;
					reg = <0x03>;
				};
			};
		};

		i2c@ff030000 {
			compatible = "cdns,i2c-r1p14";
			status = "okay";
			interrupt-parent = <0x04>;
			interrupts = <0x00 0x12 0x04>;
			reg = <0x00 0xff030000 0x00 0x1000>;
			#address-cells = <0x01>;
			#size-cells = <0x00>;
			power-domains = <0x0c 0x26>;
			clocks = <0x03 0x3e>;
			pinctrl-names = "default\0gpio";
			pinctrl-0 = <0x15>;
			pinctrl-1 = <0x16>;
			scl-gpios = <0x14 0x10 0x00>;
			sda-gpios = <0x14 0x11 0x00>;
			clock-frequency = <0x61a80>;
			phandle = <0x71>;

			i2c-mux@74 {
				compatible = "nxp,pca9548";
				#address-cells = <0x01>;
				#size-cells = <0x00>;
				reg = <0x74>;

				i2c@0 {
					#address-cells = <0x01>;
					#size-cells = <0x00>;
					reg = <0x00>;

					eeprom@54 {
						compatible = "atmel,24c08";
						reg = <0x54>;
						phandle = <0x72>;
					};
				};

				i2c@1 {
					#address-cells = <0x01>;
					#size-cells = <0x00>;
					reg = <0x01>;

					clock-generator@36 {
						compatible = "silabs,si5341";
						reg = <0x36>;
						#clock-cells = <0x02>;
						#address-cells = <0x01>;
						#size-cells = <0x00>;
						clocks = <0x17>;
						clock-names = "xtal";
						clock-output-names = "si5341";
						phandle = <0x1a>;

						out@0 {
							reg = <0x00>;
							always-on;
							phandle = <0x73>;
						};

						out@2 {
							reg = <0x02>;
							always-on;
							phandle = <0x74>;
						};

						out@3 {
							reg = <0x03>;
							always-on;
							phandle = <0x75>;
						};

						out@5 {
							reg = <0x05>;
							always-on;
							phandle = <0x76>;
						};

						out@6 {
							reg = <0x06>;
							always-on;
							phandle = <0x77>;
						};

						out@9 {
							reg = <0x09>;
							always-on;
							phandle = <0x78>;
						};
					};
				};

				i2c@2 {
					#address-cells = <0x01>;
					#size-cells = <0x00>;
					reg = <0x02>;

					clock-generator@5d {
						#clock-cells = <0x00>;
						compatible = "silabs,si570";
						reg = <0x5d>;
						temperature-stability = <0x32>;
						factory-fout = <0x11e1a300>;
						clock-frequency = <0x11e1a300>;
						clock-output-names = "si570_user";
						phandle = <0x79>;
					};
				};

				i2c@3 {
					#address-cells = <0x01>;
					#size-cells = <0x00>;
					reg = <0x03>;

					clock-generator@5d {
						#clock-cells = <0x00>;
						compatible = "silabs,si570";
						reg = <0x5d>;
						temperature-stability = <0x32>;
						factory-fout = <0x9502f90>;
						clock-frequency = <0x9502f90>;
						clock-output-names = "si570_mgt";
						phandle = <0x7a>;
					};
				};

				i2c@4 {
					#address-cells = <0x01>;
					#size-cells = <0x00>;
					reg = <0x04>;
				};

				i2c@5 {
					#address-cells = <0x01>;
					#size-cells = <0x00>;
					reg = <0x05>;

					sc18is603@2f {
						compatible = "nxp,sc18is603";
						reg = <0x2f>;
					};
				};

				i2c@6 {
					#address-cells = <0x01>;
					#size-cells = <0x00>;
					reg = <0x06>;
				};
			};

			i2c-mux@75 {
				compatible = "nxp,pca9548";
				#address-cells = <0x01>;
				#size-cells = <0x00>;
				reg = <0x75>;

				i2c@0 {
					#address-cells = <0x01>;
					#size-cells = <0x00>;
					reg = <0x00>;
				};

				i2c@1 {
					#address-cells = <0x01>;
					#size-cells = <0x00>;
					reg = <0x01>;
				};

				i2c@2 {
					#address-cells = <0x01>;
					#size-cells = <0x00>;
					reg = <0x02>;
				};

				i2c@3 {
					#address-cells = <0x01>;
					#size-cells = <0x00>;
					reg = <0x03>;

					dev@19 {
						compatible = "xxx";
						reg = <0x19>;
					};

					dev@30 {
						compatible = "xxx";
						reg = <0x30>;
					};

					dev@35 {
						compatible = "xxx";
						reg = <0x35>;
					};

					dev@36 {
						compatible = "xxx";
						reg = <0x36>;
					};

					dev@51 {
						compatible = "xxx";
						reg = <0x51>;
					};
				};

				i2c@4 {
					#address-cells = <0x01>;
					#size-cells = <0x00>;
					reg = <0x04>;
				};

				i2c@5 {
					#address-cells = <0x01>;
					#size-cells = <0x00>;
					reg = <0x05>;
				};

				i2c@6 {
					#address-cells = <0x01>;
					#size-cells = <0x00>;
					reg = <0x06>;
				};

				i2c@7 {
					#address-cells = <0x01>;
					#size-cells = <0x00>;
					reg = <0x07>;
				};
			};
		};

		memory-controller@ff960000 {
			compatible = "xlnx,zynqmp-ocmc-1.0";
			reg = <0x00 0xff960000 0x00 0x1000>;
			interrupt-parent = <0x04>;
			interrupts = <0x00 0x0a 0x04>;
			phandle = <0x7b>;
		};

		perf-monitor@ffa00000 {
			compatible = "xlnx,axi-perf-monitor";
			reg = <0x00 0xffa00000 0x00 0x10000>;
			interrupts = <0x00 0x19 0x04>;
			interrupt-parent = <0x04>;
			xlnx,enable-profile = <0x00>;
			xlnx,enable-trace = <0x00>;
			xlnx,num-monitor-slots = <0x01>;
			xlnx,enable-event-count = <0x01>;
			xlnx,enable-event-log = <0x01>;
			xlnx,have-sampled-metric-cnt = <0x01>;
			xlnx,num-of-counters = <0x08>;
			xlnx,metric-count-width = <0x20>;
			xlnx,metrics-sample-count-width = <0x20>;
			xlnx,global-count-width = <0x20>;
			xlnx,metric-count-scale = <0x01>;
			clocks = <0x03 0x1f>;
			phandle = <0x7c>;
		};

		perf-monitor@fd0b0000 {
			compatible = "xlnx,axi-perf-monitor";
			reg = <0x00 0xfd0b0000 0x00 0x10000>;
			interrupts = <0x00 0x7b 0x04>;
			interrupt-parent = <0x04>;
			xlnx,enable-profile = <0x00>;
			xlnx,enable-trace = <0x00>;
			xlnx,num-monitor-slots = <0x06>;
			xlnx,enable-event-count = <0x01>;
			xlnx,enable-event-log = <0x00>;
			xlnx,have-sampled-metric-cnt = <0x01>;
			xlnx,num-of-counters = <0x0a>;
			xlnx,metric-count-width = <0x20>;
			xlnx,metrics-sample-count-width = <0x20>;
			xlnx,global-count-width = <0x20>;
			xlnx,metric-count-scale = <0x01>;
			clocks = <0x03 0x1c>;
			phandle = <0x7d>;
		};

		perf-monitor@fd490000 {
			compatible = "xlnx,axi-perf-monitor";
			reg = <0x00 0xfd490000 0x00 0x10000>;
			interrupts = <0x00 0x7b 0x04>;
			interrupt-parent = <0x04>;
			xlnx,enable-profile = <0x00>;
			xlnx,enable-trace = <0x00>;
			xlnx,num-monitor-slots = <0x01>;
			xlnx,enable-event-count = <0x01>;
			xlnx,enable-event-log = <0x00>;
			xlnx,have-sampled-metric-cnt = <0x01>;
			xlnx,num-of-counters = <0x08>;
			xlnx,metric-count-width = <0x20>;
			xlnx,metrics-sample-count-width = <0x20>;
			xlnx,global-count-width = <0x20>;
			xlnx,metric-count-scale = <0x01>;
			clocks = <0x03 0x1c>;
			phandle = <0x7e>;
		};

		perf-monitor@ffa10000 {
			compatible = "xlnx,axi-perf-monitor";
			reg = <0x00 0xffa10000 0x00 0x10000>;
			interrupts = <0x00 0x19 0x04>;
			interrupt-parent = <0x04>;
			xlnx,enable-profile = <0x00>;
			xlnx,enable-trace = <0x00>;
			xlnx,num-monitor-slots = <0x01>;
			xlnx,enable-event-count = <0x01>;
			xlnx,enable-event-log = <0x01>;
			xlnx,have-sampled-metric-cnt = <0x01>;
			xlnx,num-of-counters = <0x08>;
			xlnx,metric-count-width = <0x20>;
			xlnx,metrics-sample-count-width = <0x20>;
			xlnx,global-count-width = <0x20>;
			xlnx,metric-count-scale = <0x01>;
			clocks = <0x03 0x1f>;
			phandle = <0x7f>;
		};

		pcie@fd0e0000 {
			compatible = "xlnx,nwl-pcie-2.11";
			status = "disabled";
			#address-cells = <0x03>;
			#size-cells = <0x02>;
			#interrupt-cells = <0x01>;
			msi-controller;
			device_type = "pci";
			interrupt-parent = <0x04>;
			interrupts = <0x00 0x76 0x04 0x00 0x75 0x04 0x00 0x74 0x04 0x00 0x73 0x04 0x00 0x72 0x04>;
			interrupt-names = "misc\0dummy\0intx\0msi1\0msi0";
			msi-parent = <0x18>;
			reg = <0x00 0xfd0e0000 0x00 0x1000 0x00 0xfd480000 0x00 0x1000 0x80 0x00 0x00 0x1000000>;
			reg-names = "breg\0pcireg\0cfg";
			ranges = <0x2000000 0x00 0xe0000000 0x00 0xe0000000 0x00 0x10000000 0x43000000 0x06 0x00 0x06 0x00 0x02 0x00>;
			interrupt-map-mask = <0x00 0x00 0x00 0x07>;
			bus-range = <0x00 0xff>;
			interrupt-map = <0x00 0x00 0x00 0x01 0x19 0x01 0x00 0x00 0x00 0x02 0x19 0x02 0x00 0x00 0x00 0x03 0x19 0x03 0x00 0x00 0x00 0x04 0x19 0x04>;
			#stream-id-cells = <0x01>;
			iommus = <0x0d 0x4d0>;
			power-domains = <0x0c 0x3b>;
			clocks = <0x03 0x17>;
			phandle = <0x18>;

			legacy-interrupt-controller {
				interrupt-controller;
				#address-cells = <0x00>;
				#interrupt-cells = <0x01>;
				phandle = <0x19>;
			};
		};

		spi@ff0f0000 {
			u-boot,dm-pre-reloc;
			compatible = "xlnx,zynqmp-qspi-1.0";
			status = "okay";
			clock-names = "ref_clk\0pclk";
			interrupts = <0x00 0x0f 0x04>;
			interrupt-parent = <0x04>;
			num-cs = <0x01>;
			reg = <0x00 0xff0f0000 0x00 0x1000 0x00 0xc0000000 0x00 0x8000000>;
			#address-cells = <0x01>;
			#size-cells = <0x00>;
			#stream-id-cells = <0x01>;
			iommus = <0x0d 0x873>;
			power-domains = <0x0c 0x2d>;
			clocks = <0x03 0x35 0x03 0x1f>;
			is-dual = <0x01>;
			spi-rx-bus-width = <0x04>;
			spi-tx-bus-width = <0x04>;
			phandle = <0x80>;

			flash@0 {
				compatible = "m25p80\0jedec,spi-nor";
				#address-cells = <0x01>;
				#size-cells = <0x01>;
				reg = <0x00>;
				spi-tx-bus-width = <0x04>;
				spi-rx-bus-width = <0x04>;
				spi-max-frequency = <0x66ff300>;
				phandle = <0x81>;

				partition@0 {
					label = "boot";
					reg = <0x00 0x100000>;
				};

				partition@1 {
					label = "bootenv";
					reg = <0x100000 0x40000>;
				};

				partition@2 {
					label = "kernel";
					reg = <0x140000 0x1600000>;
				};
			};
		};

		phy@fd400000 {
			compatible = "xlnx,zynqmp-psgtr-v1.1";
			status = "okay";
			reg = <0x00 0xfd400000 0x00 0x40000 0x00 0xfd3d0000 0x00 0x1000>;
			reg-names = "serdes\0siou";
			#phy-cells = <0x04>;
			clocks = <0x1a 0x00 0x00 0x1a 0x00 0x02 0x1a 0x00 0x03>;
			clock-names = "ref1\0ref2\0ref3";
			phandle = <0x1b>;
		};

		rtc@ffa60000 {
			compatible = "xlnx,zynqmp-rtc";
			status = "okay";
			reg = <0x00 0xffa60000 0x00 0x100>;
			interrupt-parent = <0x04>;
			interrupts = <0x00 0x1a 0x04 0x00 0x1b 0x04>;
			interrupt-names = "alarm\0sec";
			calibration = <0x7fff>;
			phandle = <0x82>;
		};

		ahci@fd0c0000 {
			compatible = "ceva,ahci-1v84";
			status = "okay";
			reg = <0x00 0xfd0c0000 0x00 0x2000>;
			interrupt-parent = <0x04>;
			interrupts = <0x00 0x85 0x04>;
			power-domains = <0x0c 0x1c>;
			resets = <0x0e 0x10>;
			#stream-id-cells = <0x04>;
			clocks = <0x03 0x16>;
			ceva,p0-cominit-params = <0x18401828>;
			ceva,p0-comwake-params = <0x614080e>;
			ceva,p0-burst-params = <0x13084a06>;
			ceva,p0-retry-params = <0x96a43ffc>;
			ceva,p1-cominit-params = <0x18401828>;
			ceva,p1-comwake-params = <0x614080e>;
			ceva,p1-burst-params = <0x13084a06>;
			ceva,p1-retry-params = <0x96a43ffc>;
			phy-names = "sata-phy";
			phys = <0x1b 0x03 0x01 0x01 0x03>;
			xlnx,tz-nonsecure-sata0 = <0x00>;
			xlnx,tz-nonsecure-sata1 = <0x00>;
			phandle = <0x83>;
		};

		mmc@ff160000 {
			u-boot,dm-pre-reloc;
			compatible = "xlnx,zynqmp-8.9a\0arasan,sdhci-8.9a";
			status = "disabled";
			interrupt-parent = <0x04>;
			interrupts = <0x00 0x30 0x04>;
			reg = <0x00 0xff160000 0x00 0x1000>;
			clock-names = "clk_xin\0clk_ahb";
			xlnx,device_id = <0x00>;
			#stream-id-cells = <0x01>;
			iommus = <0x0d 0x870>;
			power-domains = <0x0c 0x27>;
			#clock-cells = <0x01>;
			clock-output-names = "clk_out_sd0\0clk_in_sd0";
			resets = <0x0e 0x26>;
			clocks = <0x03 0x36 0x03 0x1f>;
			assigned-clocks = <0x03 0x36>;
			phandle = <0x84>;
		};

		mmc@ff170000 {
			u-boot,dm-pre-reloc;
			compatible = "xlnx,zynqmp-8.9a\0arasan,sdhci-8.9a";
			status = "okay";
			interrupt-parent = <0x04>;
			interrupts = <0x00 0x31 0x04>;
			reg = <0x00 0xff170000 0x00 0x1000>;
			clock-names = "clk_xin\0clk_ahb";
			xlnx,device_id = <0x01>;
			#stream-id-cells = <0x01>;
			iommus = <0x0d 0x871>;
			power-domains = <0x0c 0x28>;
			#clock-cells = <0x01>;
			clock-output-names = "clk_out_sd1\0clk_in_sd1";
			resets = <0x0e 0x27>;
			clocks = <0x03 0x37 0x03 0x1f>;
			assigned-clocks = <0x03 0x37>;
			pinctrl-names = "default";
			pinctrl-0 = <0x1c>;
			disable-wp;
			xlnx,mio-bank = <0x01>;
			no-1-8-v;
			clock-frequency = <0xb2cfe8b>;
			phandle = <0x85>;
		};

		smmu@fd800000 {
			compatible = "arm,mmu-500";
			reg = <0x00 0xfd800000 0x00 0x20000>;
			#iommu-cells = <0x01>;
			status = "disabled";
			#global-interrupts = <0x01>;
			interrupt-parent = <0x04>;
			interrupts = <0x00 0x9b 0x04 0x00 0x9b 0x04 0x00 0x9b 0x04 0x00 0x9b 0x04 0x00 0x9b 0x04 0x00 0x9b 0x04 0x00 0x9b 0x04 0x00 0x9b 0x04 0x00 0x9b 0x04 0x00 0x9b 0x04 0x00 0x9b 0x04 0x00 0x9b 0x04 0x00 0x9b 0x04 0x00 0x9b 0x04 0x00 0x9b 0x04 0x00 0x9b 0x04 0x00 0x9b 0x04>;
			phandle = <0x0d>;
		};

		spi@ff040000 {
			compatible = "cdns,spi-r1p6";
			status = "disabled";
			interrupt-parent = <0x04>;
			interrupts = <0x00 0x13 0x04>;
			reg = <0x00 0xff040000 0x00 0x1000>;
			clock-names = "ref_clk\0pclk";
			#address-cells = <0x01>;
			#size-cells = <0x00>;
			power-domains = <0x0c 0x23>;
			clocks = <0x03 0x3a 0x03 0x1f>;
			phandle = <0x86>;
		};

		spi@ff050000 {
			compatible = "cdns,spi-r1p6";
			status = "disabled";
			interrupt-parent = <0x04>;
			interrupts = <0x00 0x14 0x04>;
			reg = <0x00 0xff050000 0x00 0x1000>;
			clock-names = "ref_clk\0pclk";
			#address-cells = <0x01>;
			#size-cells = <0x00>;
			power-domains = <0x0c 0x24>;
			clocks = <0x03 0x3b 0x03 0x1f>;
			phandle = <0x87>;
		};

		timer@ff110000 {
			compatible = "cdns,ttc";
			status = "disabled";
			interrupt-parent = <0x04>;
			interrupts = <0x00 0x24 0x04 0x00 0x25 0x04 0x00 0x26 0x04>;
			reg = <0x00 0xff110000 0x00 0x1000>;
			timer-width = <0x20>;
			power-domains = <0x0c 0x18>;
			clocks = <0x03 0x1f>;
			phandle = <0x88>;
		};

		timer@ff120000 {
			compatible = "cdns,ttc";
			status = "disabled";
			interrupt-parent = <0x04>;
			interrupts = <0x00 0x27 0x04 0x00 0x28 0x04 0x00 0x29 0x04>;
			reg = <0x00 0xff120000 0x00 0x1000>;
			timer-width = <0x20>;
			power-domains = <0x0c 0x19>;
			clocks = <0x03 0x1f>;
			phandle = <0x89>;
		};

		timer@ff130000 {
			compatible = "cdns,ttc";
			status = "disabled";
			interrupt-parent = <0x04>;
			interrupts = <0x00 0x2a 0x04 0x00 0x2b 0x04 0x00 0x2c 0x04>;
			reg = <0x00 0xff130000 0x00 0x1000>;
			timer-width = <0x20>;
			power-domains = <0x0c 0x1a>;
			clocks = <0x03 0x1f>;
			phandle = <0x8a>;
		};

		timer@ff140000 {
			compatible = "cdns,ttc";
			status = "disabled";
			interrupt-parent = <0x04>;
			interrupts = <0x00 0x2d 0x04 0x00 0x2e 0x04 0x00 0x2f 0x04>;
			reg = <0x00 0xff140000 0x00 0x1000>;
			timer-width = <0x20>;
			power-domains = <0x0c 0x1b>;
			clocks = <0x03 0x1f>;
			phandle = <0x8b>;
		};

		serial@ff000000 {
			u-boot,dm-pre-reloc;
			compatible = "xlnx,zynqmp-uart\0cdns,uart-r1p12";
			status = "okay";
			interrupt-parent = <0x04>;
			interrupts = <0x00 0x15 0x04>;
			reg = <0x00 0xff000000 0x00 0x1000>;
			clock-names = "uart_clk\0pclk";
			power-domains = <0x0c 0x21>;
			clocks = <0x03 0x38 0x03 0x1f>;
			pinctrl-names = "default";
			pinctrl-0 = <0x1d>;
			cts-override;
			device_type = "serial";
			port-number = <0x00>;
			phandle = <0x8c>;
		};

		serial@ff010000 {
			u-boot,dm-pre-reloc;
			compatible = "xlnx,zynqmp-uart\0cdns,uart-r1p12";
			status = "disabled";
			interrupt-parent = <0x04>;
			interrupts = <0x00 0x16 0x04>;
			reg = <0x00 0xff010000 0x00 0x1000>;
			clock-names = "uart_clk\0pclk";
			power-domains = <0x0c 0x22>;
			clocks = <0x03 0x39 0x03 0x1f>;
			phandle = <0x8d>;
		};

		usb0@ff9d0000 {
			#address-cells = <0x02>;
			#size-cells = <0x02>;
			status = "okay";
			compatible = "xlnx,zynqmp-dwc3";
			reg = <0x00 0xff9d0000 0x00 0x100>;
			clock-names = "bus_clk\0ref_clk";
			power-domains = <0x0c 0x16>;
			resets = <0x0e 0x3b 0x0e 0x3d 0x0e 0x3f>;
			reset-names = "usb_crst\0usb_hibrst\0usb_apbrst";
			reset-gpios = <0x1e 0x01 0x01>;
			ranges;
			clocks = <0x03 0x20 0x03 0x22>;
			assigned-clocks = <0x03 0x20 0x03 0x22>;
			pinctrl-names = "default";
			pinctrl-0 = <0x1f>;
			phy-names = "usb3-phy";
			phys = <0x1b 0x02 0x04 0x00 0x02>;
			xlnx,tz-nonsecure = <0x01>;
			xlnx,usb-polarity = <0x00>;
			xlnx,usb-reset-mode = <0x00>;
			phandle = <0x8e>;

			usb@fe200000 {
				compatible = "snps,dwc3";
				status = "okay";
				reg = <0x00 0xfe200000 0x00 0x40000>;
				interrupt-parent = <0x04>;
				interrupt-names = "dwc_usb3\0otg\0hiber";
				interrupts = <0x00 0x41 0x04 0x00 0x45 0x04 0x00 0x4b 0x04>;
				#stream-id-cells = <0x01>;
				iommus = <0x0d 0x860>;
				snps,quirk-frame-length-adjustment = <0x20>;
				snps,refclk_fladj;
				snps,enable_guctl1_resume_quirk;
				snps,enable_guctl1_ipd_quirk;
				snps,xhci-stream-quirk;
				dr_mode = "host";
				snps,usb3_lpm_capable;
				maximum-speed = "super-speed";
				phandle = <0x8f>;
			};
		};

		usb1@ff9e0000 {
			#address-cells = <0x02>;
			#size-cells = <0x02>;
			status = "disabled";
			compatible = "xlnx,zynqmp-dwc3";
			reg = <0x00 0xff9e0000 0x00 0x100>;
			clock-names = "bus_clk\0ref_clk";
			power-domains = <0x0c 0x17>;
			resets = <0x0e 0x3c 0x0e 0x3e 0x0e 0x40>;
			reset-names = "usb_crst\0usb_hibrst\0usb_apbrst";
			ranges;
			clocks = <0x03 0x21 0x03 0x22>;
			assigned-clocks = <0x03 0x21 0x03 0x22>;
			phandle = <0x90>;

			usb@fe300000 {
				compatible = "snps,dwc3";
				status = "disabled";
				reg = <0x00 0xfe300000 0x00 0x40000>;
				interrupt-parent = <0x04>;
				interrupt-names = "dwc_usb3\0otg\0hiber";
				interrupts = <0x00 0x46 0x04 0x00 0x4a 0x04 0x00 0x4c 0x04>;
				#stream-id-cells = <0x01>;
				iommus = <0x0d 0x861>;
				snps,quirk-frame-length-adjustment = <0x20>;
				snps,refclk_fladj;
				snps,enable_guctl1_resume_quirk;
				snps,enable_guctl1_ipd_quirk;
				snps,xhci-stream-quirk;
				phandle = <0x91>;
			};
		};

		watchdog@fd4d0000 {
			compatible = "cdns,wdt-r1p2";
			status = "okay";
			interrupt-parent = <0x04>;
			interrupts = <0x00 0x71 0x01>;
			reg = <0x00 0xfd4d0000 0x00 0x1000>;
			timeout-sec = <0x3c>;
			reset-on-timeout;
			clocks = <0x03 0x4b>;
			phandle = <0x92>;
		};

		watchdog@ff150000 {
			compatible = "cdns,wdt-r1p2";
			status = "okay";
			interrupt-parent = <0x04>;
			interrupts = <0x00 0x34 0x01>;
			reg = <0x00 0xff150000 0x00 0x1000>;
			timeout-sec = <0x0a>;
			clocks = <0x03 0x70>;
			phandle = <0x93>;
		};

		ams@ffa50000 {
			compatible = "xlnx,zynqmp-ams";
			status = "okay";
			interrupt-parent = <0x04>;
			interrupts = <0x00 0x38 0x04>;
			interrupt-names = "ams-irq";
			reg = <0x00 0xffa50000 0x00 0x800>;
			reg-names = "ams-base";
			#address-cells = <0x02>;
			#size-cells = <0x02>;
			#io-channel-cells = <0x01>;
			ranges;
			clocks = <0x03 0x46>;
			phandle = <0x94>;

			ams_ps@ffa50800 {
				compatible = "xlnx,zynqmp-ams-ps";
				status = "okay";
				reg = <0x00 0xffa50800 0x00 0x400>;
				phandle = <0x95>;
			};

			ams_pl@ffa50c00 {
				compatible = "xlnx,zynqmp-ams-pl";
				status = "okay";
				reg = <0x00 0xffa50c00 0x00 0x400>;
				phandle = <0x96>;
			};
		};

		dma-controller@fd4c0000 {
			compatible = "xlnx,zynqmp-dpdma";
			status = "okay";
			reg = <0x00 0xfd4c0000 0x00 0x1000>;
			interrupts = <0x00 0x7a 0x04>;
			interrupt-parent = <0x04>;
			clock-names = "axi_clk";
			power-domains = <0x0c 0x29>;
			dma-channels = <0x06>;
			#stream-id-cells = <0x01>;
			iommus = <0x0d 0xce4>;
			#dma-cells = <0x01>;
			clocks = <0x03 0x14>;
			assigned-clocks = <0x03 0x14>;
			phandle = <0x21>;
		};

		dp_aud@fd4ac000 {
			compatible = "xlnx,zynqmp-dpaud-setting\0syscon";
			reg = <0x00 0xfd4ac000 0x00 0x1000>;
			phandle = <0x20>;
		};

		display@fd4a0000 {
			u-boot,dm-pre-reloc;
			compatible = "xlnx,zynqmp-dpsub-1.7";
			status = "okay";
			reg = <0x00 0xfd4a0000 0x00 0x1000 0x00 0xfd4aa000 0x00 0x1000 0x00 0xfd4ab000 0x00 0x1000>;
			reg-names = "dp\0blend\0av_buf";
			xlnx,dpaud-reg = <0x20>;
			interrupts = <0x00 0x77 0x04>;
			interrupt-parent = <0x04>;
			#stream-id-cells = <0x01>;
			iommus = <0x0d 0xce3>;
			clock-names = "dp_apb_clk\0dp_aud_clk\0dp_vtc_pixel_clk_in";
			power-domains = <0x0c 0x29>;
			resets = <0x0e 0x03>;
			dma-names = "vid0\0vid1\0vid2\0gfx0";
			dmas = <0x21 0x00 0x21 0x01 0x21 0x02 0x21 0x03>;
			clocks = <0x22 0x03 0x11 0x03 0x10>;
			assigned-clocks = <0x03 0x12 0x03 0x11 0x03 0x10>;
			phy-names = "dp-phy0\0dp-phy1";
			phys = <0x1b 0x01 0x06 0x00 0x01 0x1b 0x00 0x06 0x01 0x01>;
			xlnx,max-lanes = <0x02>;
			phandle = <0x97>;

			i2c-bus {
			};

			zynqmp_dp_snd_codec0 {
				compatible = "xlnx,dp-snd-codec";
				clock-names = "aud_clk";
				clocks = <0x03 0x11>;
				status = "okay";
				phandle = <0x25>;
			};

			zynqmp_dp_snd_pcm0 {
				compatible = "xlnx,dp-snd-pcm0";
				dmas = <0x21 0x04>;
				dma-names = "tx";
				status = "okay";
				phandle = <0x23>;
			};

			zynqmp_dp_snd_pcm1 {
				compatible = "xlnx,dp-snd-pcm1";
				dmas = <0x21 0x05>;
				dma-names = "tx";
				status = "okay";
				phandle = <0x24>;
			};

			zynqmp_dp_snd_card {
				compatible = "xlnx,dp-snd-card";
				xlnx,dp-snd-pcm = <0x23 0x24>;
				xlnx,dp-snd-codec = <0x25>;
				status = "okay";
				phandle = <0x98>;
			};
		};
	};

	fclk0 {
		status = "okay";
		compatible = "xlnx,fclk";
		clocks = <0x03 0x47>;
		phandle = <0x99>;
	};

	fclk1 {
		status = "okay";
		compatible = "xlnx,fclk";
		clocks = <0x03 0x48>;
		phandle = <0x9a>;
	};

	fclk2 {
		status = "okay";
		compatible = "xlnx,fclk";
		clocks = <0x03 0x49>;
		phandle = <0x9b>;
	};

	fclk3 {
		status = "okay";
		compatible = "xlnx,fclk";
		clocks = <0x03 0x4a>;
		phandle = <0x9c>;
	};

	pss_ref_clk {
		u-boot,dm-pre-reloc;
		compatible = "fixed-clock";
		#clock-cells = <0x00>;
		clock-frequency = <0x1fca055>;
		phandle = <0x06>;
	};

	video_clk {
		u-boot,dm-pre-reloc;
		compatible = "fixed-clock";
		#clock-cells = <0x00>;
		clock-frequency = <0x19bfcc0>;
		phandle = <0x07>;
	};

	pss_alt_ref_clk {
		u-boot,dm-pre-reloc;
		compatible = "fixed-clock";
		#clock-cells = <0x00>;
		clock-frequency = <0x00>;
		phandle = <0x08>;
	};

	gt_crx_ref_clk {
		u-boot,dm-pre-reloc;
		compatible = "fixed-clock";
		#clock-cells = <0x00>;
		clock-frequency = <0x66ff300>;
		phandle = <0x0a>;
	};

	aux_ref_clk {
		u-boot,dm-pre-reloc;
		compatible = "fixed-clock";
		#clock-cells = <0x00>;
		clock-frequency = <0x19bfcc0>;
		phandle = <0x09>;
	};

	dp_aclk {
		compatible = "fixed-clock";
		#clock-cells = <0x00>;
		clock-frequency = <0x5f5e100>;
		clock-accuracy = <0x64>;
		phandle = <0x22>;
	};

	gpio-keys {
		compatible = "gpio-keys";
		autorepeat;

		sw19 {
			label = "sw19";
			gpios = <0x14 0x16 0x00>;
			linux,code = <0x6c>;
			wakeup-source;
			autorepeat;
		};
	};

	leds {
		compatible = "gpio-leds";

		heartbeat-led {
			label = "heartbeat";
			gpios = <0x14 0x17 0x00>;
			linux,default-trigger = "heartbeat";
		};
	};

	chosen {
		nvmem0 = "/axi/i2c@ff030000/i2c-mux@74/i2c@0/eeprom@54";
		bootargs = " earlycon console=ttyPS0,115200 clk_ignore_unused root=/dev/ram0 rw";
		stdout-path = "serial0:115200n8";
	};

	ina226-u67 {
		compatible = "iio-hwmon";
		io-channels = <0x26 0x00 0x26 0x01 0x26 0x02 0x26 0x03>;
	};

	ina226-u59 {
		compatible = "iio-hwmon";
		io-channels = <0x27 0x00 0x27 0x01 0x27 0x02 0x27 0x03>;
	};

	ina226-u61 {
		compatible = "iio-hwmon";
		io-channels = <0x28 0x00 0x28 0x01 0x28 0x02 0x28 0x03>;
	};

	ina226-u60 {
		compatible = "iio-hwmon";
		io-channels = <0x29 0x00 0x29 0x01 0x29 0x02 0x29 0x03>;
	};

	ina226-u64 {
		compatible = "iio-hwmon";
		io-channels = <0x2a 0x00 0x2a 0x01 0x2a 0x02 0x2a 0x03>;
	};

	ina226-u69 {
		compatible = "iio-hwmon";
		io-channels = <0x2b 0x00 0x2b 0x01 0x2b 0x02 0x2b 0x03>;
	};

	ina226-u66 {
		compatible = "iio-hwmon";
		io-channels = <0x2c 0x00 0x2c 0x01 0x2c 0x02 0x2c 0x03>;
	};

	ina226-u65 {
		compatible = "iio-hwmon";
		io-channels = <0x2d 0x00 0x2d 0x01 0x2d 0x02 0x2d 0x03>;
	};

	ina226-u63 {
		compatible = "iio-hwmon";
		io-channels = <0x2e 0x00 0x2e 0x01 0x2e 0x02 0x2e 0x03>;
	};

	ina226-u3 {
		compatible = "iio-hwmon";
		io-channels = <0x2f 0x00 0x2f 0x01 0x2f 0x02 0x2f 0x03>;
	};

	ina226-u71 {
		compatible = "iio-hwmon";
		io-channels = <0x30 0x00 0x30 0x01 0x30 0x02 0x30 0x03>;
	};

	ina226-u77 {
		compatible = "iio-hwmon";
		io-channels = <0x31 0x00 0x31 0x01 0x31 0x02 0x31 0x03>;
	};

	ina226-u73 {
		compatible = "iio-hwmon";
		io-channels = <0x32 0x00 0x32 0x01 0x32 0x02 0x32 0x03>;
	};

	ina226-u79 {
		compatible = "iio-hwmon";
		io-channels = <0x33 0x00 0x33 0x01 0x33 0x02 0x33 0x03>;
	};

	ref48M {
		compatible = "fixed-clock";
		#clock-cells = <0x00>;
		clock-frequency = <0x2dc6c00>;
		phandle = <0x17>;
	};

	aliases {
		ethernet0 = "/axi/ethernet@ff0e0000";
		i2c0 = "/axi/i2c@ff020000";
		i2c1 = "/axi/i2c@ff030000";
		serial0 = "/axi/serial@ff000000";
		spi0 = "/axi/spi@ff0f0000";
	};

	memory {
		device_type = "memory";
		reg = <0x00 0x00 0x00 0x80000000 0x08 0x00 0x00 0x80000000>;
	};

	__symbols__ {
		cpu0 = "/cpus/cpu@0";
		cpu1 = "/cpus/cpu@1";
		cpu2 = "/cpus/cpu@2";
		cpu3 = "/cpus/cpu@3";
		CPU_SLEEP_0 = "/cpus/idle-states/cpu-sleep-0";
		cpu_opp_table = "/cpu-opp-table";
		zynqmp_ipi = "/zynqmp_ipi";
		ipi_mailbox_pmu1 = "/zynqmp_ipi/mailbox@ff990400";
		dcc = "/dcc";
		zynqmp_firmware = "/firmware/zynqmp-firmware";
		zynqmp_power = "/firmware/zynqmp-firmware/zynqmp-power";
		soc_revision = "/firmware/zynqmp-firmware/nvmem_firmware/soc_revision@0";
		efuse_dna = "/firmware/zynqmp-firmware/nvmem_firmware/efuse_dna@c";
		efuse_usr0 = "/firmware/zynqmp-firmware/nvmem_firmware/efuse_usr0@20";
		efuse_usr1 = "/firmware/zynqmp-firmware/nvmem_firmware/efuse_usr1@24";
		efuse_usr2 = "/firmware/zynqmp-firmware/nvmem_firmware/efuse_usr2@28";
		efuse_usr3 = "/firmware/zynqmp-firmware/nvmem_firmware/efuse_usr3@2c";
		efuse_usr4 = "/firmware/zynqmp-firmware/nvmem_firmware/efuse_usr4@30";
		efuse_usr5 = "/firmware/zynqmp-firmware/nvmem_firmware/efuse_usr5@34";
		efuse_usr6 = "/firmware/zynqmp-firmware/nvmem_firmware/efuse_usr6@38";
		efuse_usr7 = "/firmware/zynqmp-firmware/nvmem_firmware/efuse_usr7@3c";
		efuse_miscusr = "/firmware/zynqmp-firmware/nvmem_firmware/efuse_miscusr@40";
		efuse_chash = "/firmware/zynqmp-firmware/nvmem_firmware/efuse_chash@50";
		efuse_pufmisc = "/firmware/zynqmp-firmware/nvmem_firmware/efuse_pufmisc@54";
		efuse_sec = "/firmware/zynqmp-firmware/nvmem_firmware/efuse_sec@58";
		efuse_spkid = "/firmware/zynqmp-firmware/nvmem_firmware/efuse_spkid@5c";
		efuse_ppk0hash = "/firmware/zynqmp-firmware/nvmem_firmware/efuse_ppk0hash@a0";
		efuse_ppk1hash = "/firmware/zynqmp-firmware/nvmem_firmware/efuse_ppk1hash@d0";
		zynqmp_pcap = "/firmware/zynqmp-firmware/pcap";
		xlnx_aes = "/firmware/zynqmp-firmware/zynqmp-aes";
		zynqmp_reset = "/firmware/zynqmp-firmware/reset-controller";
		pinctrl0 = "/firmware/zynqmp-firmware/pinctrl";
		pinctrl_i2c0_default = "/firmware/zynqmp-firmware/pinctrl/i2c0-default";
		pinctrl_i2c0_gpio = "/firmware/zynqmp-firmware/pinctrl/i2c0-gpio";
		pinctrl_i2c1_default = "/firmware/zynqmp-firmware/pinctrl/i2c1-default";
		pinctrl_i2c1_gpio = "/firmware/zynqmp-firmware/pinctrl/i2c1-gpio";
		pinctrl_uart0_default = "/firmware/zynqmp-firmware/pinctrl/uart0-default";
		pinctrl_usb0_default = "/firmware/zynqmp-firmware/pinctrl/usb0-default";
		pinctrl_gem3_default = "/firmware/zynqmp-firmware/pinctrl/gem3-default";
		pinctrl_sdhci1_default = "/firmware/zynqmp-firmware/pinctrl/sdhci1-default";
		pinctrl_gpio_default = "/firmware/zynqmp-firmware/pinctrl/gpio-default";
		xlnx_keccak_384 = "/firmware/zynqmp-firmware/sha384";
		xlnx_rsa = "/firmware/zynqmp-firmware/zynqmp-rsa";
		modepin_gpio = "/firmware/zynqmp-firmware/gpio";
		zynqmp_clk = "/firmware/zynqmp-firmware/clock-controller";
		fpga_full = "/fpga-full";
		amba = "/axi";
		can0 = "/axi/can@ff060000";
		can1 = "/axi/can@ff070000";
		cci = "/axi/cci@fd6e0000";
		fpd_dma_chan1 = "/axi/dma-controller@fd500000";
		fpd_dma_chan2 = "/axi/dma-controller@fd510000";
		fpd_dma_chan3 = "/axi/dma-controller@fd520000";
		fpd_dma_chan4 = "/axi/dma-controller@fd530000";
		fpd_dma_chan5 = "/axi/dma-controller@fd540000";
		fpd_dma_chan6 = "/axi/dma-controller@fd550000";
		fpd_dma_chan7 = "/axi/dma-controller@fd560000";
		fpd_dma_chan8 = "/axi/dma-controller@fd570000";
		gic = "/axi/gic: interrupt-controller@f9010000";
		gpu = "/axi/gpu@fd4b0000";
		lpd_dma_chan1 = "/axi/dma-controller@ffa80000";
		lpd_dma_chan2 = "/axi/dma-controller@ffa90000";
		lpd_dma_chan3 = "/axi/dma-controller@ffaa0000";
		lpd_dma_chan4 = "/axi/dma-controller@ffab0000";
		lpd_dma_chan5 = "/axi/dma-controller@ffac0000";
		lpd_dma_chan6 = "/axi/dma-controller@ffad0000";
		lpd_dma_chan7 = "/axi/dma-controller@ffae0000";
		lpd_dma_chan8 = "/axi/dma-controller@ffaf0000";
		mc = "/axi/memory-controller@fd070000";
		nand0 = "/axi/nand-controller@ff100000";
		gem0 = "/axi/ethernet@ff0b0000";
		gem1 = "/axi/ethernet@ff0c0000";
		gem2 = "/axi/ethernet@ff0d0000";
		gem3 = "/axi/ethernet@ff0e0000";
		phy0 = "/axi/ethernet@ff0e0000/ethernet-phy@c";
		gpio = "/axi/gpio@ff0a0000";
		i2c0 = "/axi/i2c@ff020000";
		tca6416_u22 = "/axi/i2c@ff020000/gpio@20";
		u67 = "/axi/i2c@ff020000/i2c-mux@75/i2c@0/ina226@40";
		u59 = "/axi/i2c@ff020000/i2c-mux@75/i2c@0/ina226@41";
		u61 = "/axi/i2c@ff020000/i2c-mux@75/i2c@0/ina226@42";
		u60 = "/axi/i2c@ff020000/i2c-mux@75/i2c@0/ina226@43";
		u64 = "/axi/i2c@ff020000/i2c-mux@75/i2c@0/ina226@45";
		u69 = "/axi/i2c@ff020000/i2c-mux@75/i2c@0/ina226@46";
		u66 = "/axi/i2c@ff020000/i2c-mux@75/i2c@0/ina226@47";
		u65 = "/axi/i2c@ff020000/i2c-mux@75/i2c@0/ina226@48";
		u63 = "/axi/i2c@ff020000/i2c-mux@75/i2c@0/ina226@49";
		u3 = "/axi/i2c@ff020000/i2c-mux@75/i2c@0/ina226@4a";
		u71 = "/axi/i2c@ff020000/i2c-mux@75/i2c@0/ina226@4b";
		u77 = "/axi/i2c@ff020000/i2c-mux@75/i2c@0/ina226@4c";
		u73 = "/axi/i2c@ff020000/i2c-mux@75/i2c@0/ina226@4d";
		u79 = "/axi/i2c@ff020000/i2c-mux@75/i2c@0/ina226@4e";
		irps5401_43 = "/axi/i2c@ff020000/i2c-mux@75/i2c@2/irps5401@43";
		irps5401_44 = "/axi/i2c@ff020000/i2c-mux@75/i2c@2/irps5401@44";
		irps5401_45 = "/axi/i2c@ff020000/i2c-mux@75/i2c@2/irps5401@45";
		i2c1 = "/axi/i2c@ff030000";
		eeprom = "/axi/i2c@ff030000/i2c-mux@74/i2c@0/eeprom@54";
		si5341 = "/axi/i2c@ff030000/i2c-mux@74/i2c@1/clock-generator@36";
		si5341_0 = "/axi/i2c@ff030000/i2c-mux@74/i2c@1/clock-generator@36/out@0";
		si5341_2 = "/axi/i2c@ff030000/i2c-mux@74/i2c@1/clock-generator@36/out@2";
		si5341_3 = "/axi/i2c@ff030000/i2c-mux@74/i2c@1/clock-generator@36/out@3";
		si5341_5 = "/axi/i2c@ff030000/i2c-mux@74/i2c@1/clock-generator@36/out@5";
		si5341_6 = "/axi/i2c@ff030000/i2c-mux@74/i2c@1/clock-generator@36/out@6";
		si5341_9 = "/axi/i2c@ff030000/i2c-mux@74/i2c@1/clock-generator@36/out@9";
		si570_1 = "/axi/i2c@ff030000/i2c-mux@74/i2c@2/clock-generator@5d";
		si570_2 = "/axi/i2c@ff030000/i2c-mux@74/i2c@3/clock-generator@5d";
		ocm = "/axi/memory-controller@ff960000";
		perf_monitor_ocm = "/axi/perf-monitor@ffa00000";
		perf_monitor_ddr = "/axi/perf-monitor@fd0b0000";
		perf_monitor_cci = "/axi/perf-monitor@fd490000";
		perf_monitor_lpd = "/axi/perf-monitor@ffa10000";
		pcie = "/axi/pcie@fd0e0000";
		pcie_intc = "/axi/pcie@fd0e0000/legacy-interrupt-controller";
		qspi = "/axi/spi@ff0f0000";
		flash0 = "/axi/spi@ff0f0000/flash@0";
		psgtr = "/axi/phy@fd400000";
		rtc = "/axi/rtc@ffa60000";
		sata = "/axi/ahci@fd0c0000";
		sdhci0 = "/axi/mmc@ff160000";
		sdhci1 = "/axi/mmc@ff170000";
		smmu = "/axi/smmu@fd800000";
		spi0 = "/axi/spi@ff040000";
		spi1 = "/axi/spi@ff050000";
		ttc0 = "/axi/timer@ff110000";
		ttc1 = "/axi/timer@ff120000";
		ttc2 = "/axi/timer@ff130000";
		ttc3 = "/axi/timer@ff140000";
		uart0 = "/axi/serial@ff000000";
		uart1 = "/axi/serial@ff010000";
		usb0 = "/axi/usb0@ff9d0000";
		dwc3_0 = "/axi/usb0@ff9d0000/usb@fe200000";
		usb1 = "/axi/usb1@ff9e0000";
		dwc3_1 = "/axi/usb1@ff9e0000/usb@fe300000";
		watchdog0 = "/axi/watchdog@fd4d0000";
		lpd_watchdog = "/axi/watchdog@ff150000";
		xilinx_ams = "/axi/ams@ffa50000";
		ams_ps = "/axi/ams@ffa50000/ams_ps@ffa50800";
		ams_pl = "/axi/ams@ffa50000/ams_pl@ffa50c00";
		zynqmp_dpdma = "/axi/dma-controller@fd4c0000";
		zynqmp_dpaud_setting = "/axi/dp_aud@fd4ac000";
		zynqmp_dpsub = "/axi/display@fd4a0000";
		zynqmp_dp_snd_codec0 = "/axi/display@fd4a0000/zynqmp_dp_snd_codec0";
		zynqmp_dp_snd_pcm0 = "/axi/display@fd4a0000/zynqmp_dp_snd_pcm0";
		zynqmp_dp_snd_pcm1 = "/axi/display@fd4a0000/zynqmp_dp_snd_pcm1";
		zynqmp_dp_snd_card0 = "/axi/display@fd4a0000/zynqmp_dp_snd_card";
		fclk0 = "/fclk0";
		fclk1 = "/fclk1";
		fclk2 = "/fclk2";
		fclk3 = "/fclk3";
		pss_ref_clk = "/pss_ref_clk";
		video_clk = "/video_clk";
		pss_alt_ref_clk = "/pss_alt_ref_clk";
		gt_crx_ref_clk = "/gt_crx_ref_clk";
		aux_ref_clk = "/aux_ref_clk";
		dp_aclk = "/dp_aclk";
		ref48 = "/ref48M";
	};
};
